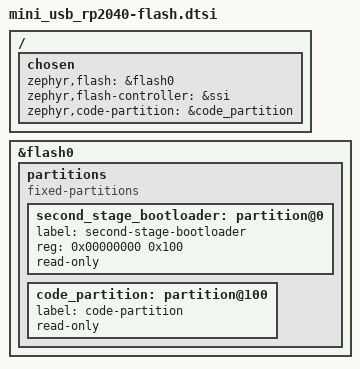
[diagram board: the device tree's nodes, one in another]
/*
 * Copyright (c) 2025 TiaC Systems
 * SPDX-License-Identifier: Apache-2.0
 */

/ {
	chosen {
		zephyr,flash = &flash0;
		zephyr,flash-controller = &ssi;
		zephyr,code-partition = &code_partition;
	};
};

&flash0 {
	partitions {
		compatible = "fixed-partitions";
		#address-cells = <1>;
		#size-cells = <1>;

		/* Reserved memory for the RP2040 second stage bootloader */
		second_stage_bootloader: partition@0 {
			label = "second-stage-bootloader";
			reg = <0x00000000 0x100>;
			read-only;
		};

		/* Rest for code */
		code_partition: partition@100 {
			label = "code-partition";
			read-only;
		};
	};
};
